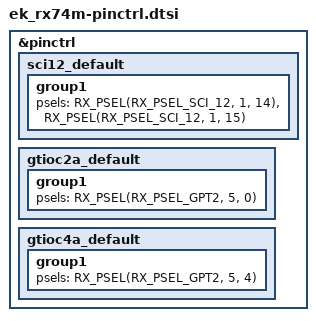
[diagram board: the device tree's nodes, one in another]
/*
 * Copyright (c) 2026 Renesas Electronics Corporation
 * SPDX-License-Identifier: Apache-2.0
 */

&pinctrl {
	sci12_default: sci12_default {
		group1 {
			psels = <RX_PSEL(RX_PSEL_SCI_12, 1, 14)>, /* TX */
				<RX_PSEL(RX_PSEL_SCI_12, 1, 15)>; /* RX */
		};
	};

	gtioc2a_default: gtioc2a_default {
		group1 {
			psels = <RX_PSEL(RX_PSEL_GPT2, 5, 0)>; /* GTIOC2A */
		};
	};

	gtioc4a_default: gtioc4a_default {
		group1 {
			psels = <RX_PSEL(RX_PSEL_GPT2, 5, 4)>; /* GTIOC4A */
		};
	};
};
